AUTOSAR XML (schema 4-3-0)
standard types defined: UINT8, UINT16, UINT32, UINT64, SINT8, SINT16, SINT32, FLOAT32, FLOAT64
package /Pkg_ErrorMgrAgg_1_0_QM/ComponentTypes
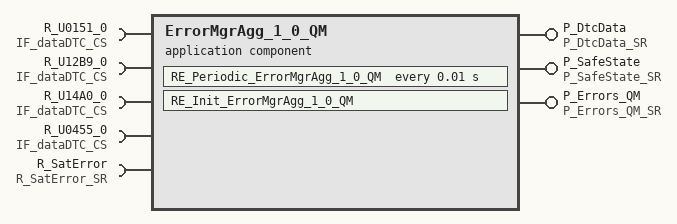
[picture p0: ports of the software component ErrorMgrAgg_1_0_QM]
  application sw component type ErrorMgrAgg_1_0_QM
    provide port P_DtcData: provided-interface=P_DtcData_SR
      provided-com-specs:
        data-element=Data_DtcStatus_QM, init-value=constant-reference=init_Data_DtcStatus_QM
        data-element=Data_DtcAddData_QM, init-value=constant-reference=init_Data_DtcAddData_QM
    provide port P_SafeState: nonqueued-sender-com-spec{data-element=SafeStateOp, init-value=constant-reference=init_SafeStateOp}, provided-interface=P_SafeState_SR
    provide port P_Errors_QM: nonqueued-sender-com-spec=data-element=Errors_QM, provided-interface=P_Errors_QM_SR
    5 x require port:
      R_U0151_0: client-com-spec=dTCinfo_v, required-interface=IF_dataDTC_CS
      R_U12B9_0: client-com-spec=dTCinfo_v, required-interface=IF_dataDTC_CS
      R_U14A0_0: client-com-spec=dTCinfo_v, required-interface=IF_dataDTC_CS
      R_U0455_0: client-com-spec=dTCinfo_v, required-interface=IF_dataDTC_CS
      R_SatError: required-interface=R_SatError_SR
        required-com-specs:
          data-element=Data_ErrorMgr_ErrorCommPack_1_0_QM, init-value=constant-reference=init_Data_ErrorMgr_ErrorCommPack_1_0_QM
          data-element=Data_ErrorMgr_ErrorCommPack_2_0_QM, init-value=constant-reference=init_Data_ErrorMgr_ErrorCommPack_2_0_QM
          data-element=Data_ErrorMgr_ErrorCommPack_2_1_QM, init-value=constant-reference=init_Data_ErrorMgr_ErrorCommPack_2_1_QM
          data-element=Data_ErrorMgr_ErrorCommPack_QNX_QM, init-value=constant-reference=init_Data_ErrorMgr_ErrorCommPack_QNX_QM
    behavior ErrorMgrAgg_1_0_QM_InternalBehavior: handle-termination-and-restart=NO-SUPPORT
      timing event TMT_RE_Periodic_ErrorMgrAgg_1_0_QM: start-on-event=RE_Periodic_ErrorMgrAgg_1_0_QM, period=0.01
      init event InitEvent: start-on-event=RE_Init_ErrorMgrAgg_1_0_QM
      port-api-options:
        enable-take-address=false, indirect-api=false, port=P_DtcData
        enable-take-address=false, indirect-api=false, port=P_Errors_QM
        enable-take-address=false, indirect-api=false, port=P_SafeState
        enable-take-address=false, indirect-api=false, port=R_SatError
        enable-take-address=false, indirect-api=false, port=R_U0151_0
        enable-take-address=false, indirect-api=false, port=R_U0455_0
        enable-take-address=false, indirect-api=false, port=R_U12B9_0
        enable-take-address=false, indirect-api=false, port=R_U14A0_0
      runnable RE_Periodic_ErrorMgrAgg_1_0_QM  # Periodic Runnable of Satellite
        data-receive-point-by-arguments:
          4 x access:
            REC_R_SatError_Data_ErrorMgr_ErrorCommPack_1_0_QM: accessed-variable=R_SatError.Data_ErrorMgr_ErrorCommPack_1_0_QM
            REC_R_SatError_Data_ErrorMgr_ErrorCommPack_2_0_QM: accessed-variable=R_SatError.Data_ErrorMgr_ErrorCommPack_2_0_QM
            REC_R_SatError_Data_ErrorMgr_ErrorCommPack_2_1_QM: accessed-variable=R_SatError.Data_ErrorMgr_ErrorCommPack_2_1_QM
            REC_R_SatError_Data_ErrorMgr_ErrorCommPack_QNX_QM: accessed-variable=R_SatError.Data_ErrorMgr_ErrorCommPack_QNX_QM
        data-send-points:
          4 x access:
            SEND_P_DtcData_Data_DtcStatus_QM: accessed-variable=P_DtcData.Data_DtcStatus_QM
            SEND_P_DtcData_Data_DtcAddData_QM: accessed-variable=P_DtcData.Data_DtcAddData_QM
            SEND_P_SafeState_SafeStateOp: accessed-variable=P_SafeState.SafeStateOp
            SEND_P_Errors_QM_Errors_QM: accessed-variable=P_Errors_QM.Errors_QM
        4 x sync call, all with timeout=0:
          SC_R_U0151_0_dTCinfo_v: operation=R_U0151_0.dTCinfo_v
          SC_R_U12B9_0_dTCinfo_v: operation=R_U12B9_0.dTCinfo_v
          SC_R_U14A0_0_dTCinfo_v: operation=R_U14A0_0.dTCinfo_v
          SC_R_U0455_0_dTCinfo_v: operation=R_U0455_0.dTCinfo_v
      runnable RE_Init_ErrorMgrAgg_1_0_QM  # Init Runnable
  swc implementation ErrorMgrAgg_1_0_QM_Implementation: programming-language=C, vendor-id=0, behavior=ErrorMgrAgg_1_0_QM_InternalBehavior
    code-descriptors:
      code Default: artifact-descriptors=autosar-engineering-object={short-label=Default, category=SWSRC}
package /Pkg_ErrorMgrAgg_1_0_QM/Constant
  8 x constant specification:
    init_Data_DtcStatus_QM: value-spec=fields=[0, 0, 0, 0]
    init_Data_DtcAddData_QM: value-spec=fields=[[0, 0, 0, 0], [0, 0, 0, 0], [0, 0, 0, 0], [0, 0, 0, 0]]
    init_SafeStateOp: value-spec=fields=16 x 0
    init_Errors_QM: value-spec=[0]
    init_Data_ErrorMgr_ErrorCommPack_1_0_QM: value-spec=fields=[0, 0, 12 x 0, 12 x fields=[0, 0, 0, 0]]
    init_Data_ErrorMgr_ErrorCommPack_2_0_QM: value-spec=fields=[0, 0, [0], [0, 0, 0], [fields=[0, 0, 0, 0]]]
    init_Data_ErrorMgr_ErrorCommPack_2_1_QM: value-spec=fields=[0, 0, [0], [0, 0, 0], [fields=[0, 0, 0, 0]]]
    init_Data_ErrorMgr_ErrorCommPack_QNX_QM: value-spec=fields=[0, 0, [0], [0, 0, 0], [fields=[0, 0, 0, 0]]]
package /Pkg_ErrorMgrAgg_1_0_QM/ImplementationDataTypes
  34 x impl type, all with type-emitter=RTE:
    BOOL: implementation-data-type=boolean
    ErrorMgr_ErrorField: implementation-data-type=uint8
    Error1_0QM_arr: category=ARRAY
      element Elem_ErrorMgr_ErrorField: array-size=12, array-size-semantics=FIXED-SIZE, implementation-data-type=ErrorMgr_ErrorField
    Data1_0QM_arr: category=ARRAY
      element Elem_ErrorMgr_stAddData: array-size=12, array-size-semantics=FIXED-SIZE, implementation-data-type=ErrorMgr_stAddData
    Error1_0B_arr: category=ARRAY
      element Elem_ErrorMgr_ErrorField: array-size=400, array-size-semantics=FIXED-SIZE, implementation-data-type=ErrorMgr_ErrorField
    Data1_0B_arr: category=ARRAY
      element Elem_ErrorMgr_stAddData: array-size=400, array-size-semantics=FIXED-SIZE, implementation-data-type=ErrorMgr_stAddData
    Error2_0QM_arr: category=ARRAY
      element Elem_ErrorMgr_ErrorField: array-size=1, array-size-semantics=FIXED-SIZE, implementation-data-type=ErrorMgr_ErrorField
    Padding2_0QM_arr: category=ARRAY
      element Elem_ErrorMgr_ErrorField: array-size=3, array-size-semantics=FIXED-SIZE, implementation-data-type=ErrorMgr_ErrorField
    Data2_0QM_arr: category=ARRAY
      element Elem_ErrorMgr_stAddData: array-size=1, array-size-semantics=FIXED-SIZE, implementation-data-type=ErrorMgr_stAddData
    Error2_0B_arr: category=ARRAY
      element Elem_ErrorMgr_ErrorField: array-size=144, array-size-semantics=FIXED-SIZE, implementation-data-type=ErrorMgr_ErrorField
    Data2_0B_arr: category=ARRAY
      element Elem_ErrorMgr_stAddData: array-size=144, array-size-semantics=FIXED-SIZE, implementation-data-type=ErrorMgr_stAddData
    Error2_1QM_arr: category=ARRAY
      element Elem_ErrorMgr_ErrorField: array-size=1, array-size-semantics=FIXED-SIZE, implementation-data-type=ErrorMgr_ErrorField
    Padding2_1QM_arr: category=ARRAY
      element Elem_ErrorMgr_ErrorField: array-size=3, array-size-semantics=FIXED-SIZE, implementation-data-type=ErrorMgr_ErrorField
    Data2_1QM_arr: category=ARRAY
      element Elem_ErrorMgr_stAddData: array-size=1, array-size-semantics=FIXED-SIZE, implementation-data-type=ErrorMgr_stAddData
    Error2_1B_arr: category=ARRAY
      element Elem_ErrorMgr_ErrorField: array-size=548, array-size-semantics=FIXED-SIZE, implementation-data-type=ErrorMgr_ErrorField
    Data2_1B_arr: category=ARRAY
      element Elem_ErrorMgr_stAddData: array-size=548, array-size-semantics=FIXED-SIZE, implementation-data-type=ErrorMgr_stAddData
    ErrorQNXQM_arr: category=ARRAY
      element Elem_ErrorMgr_ErrorField: array-size=1, array-size-semantics=FIXED-SIZE, implementation-data-type=ErrorMgr_ErrorField
    PaddingQNXQM_arr: category=ARRAY
      element Elem_ErrorMgr_ErrorField: array-size=3, array-size-semantics=FIXED-SIZE, implementation-data-type=ErrorMgr_ErrorField
    DataQNXQM_arr: category=ARRAY
      element Elem_ErrorMgr_stAddData: array-size=1, array-size-semantics=FIXED-SIZE, implementation-data-type=ErrorMgr_stAddData
    ErrorQNXB_arr: category=ARRAY
      element Elem_ErrorMgr_ErrorField: array-size=8, array-size-semantics=FIXED-SIZE, implementation-data-type=ErrorMgr_ErrorField
    DataQNXB_arr: category=ARRAY
      element Elem_ErrorMgr_stAddData: array-size=8, array-size-semantics=FIXED-SIZE, implementation-data-type=ErrorMgr_stAddData
    AdditionalData_arr: category=ARRAY
      element Elem_uint8: array-size=4, array-size-semantics=FIXED-SIZE, implementation-data-type=uint8
    SafeStateActive_arr: category=ARRAY
      element Elem_uint8: array-size=16, array-size-semantics=FIXED-SIZE, implementation-data-type=uint8
    ErrorListArr_QM: category=ARRAY
      element Elem_uint32: array-size=1, array-size-semantics=FIXED-SIZE, implementation-data-type=uint32
    ErrorMgr_enSafeStates: compu {0=ErrorMgr_SafeState_safestate1, 1=ErrorMgr_SafeState_safestate16, 2=ErrorMgr_SafeState_safestate23, 3=ErrorMgr_SafeState_safestate24, 4=ErrorMgr_SafeState_safestate17, 5=ErrorMgr_SafeState_safestate13, 6=ErrorMgr_SafeState_safestate12, 7=ErrorMgr_SafeState_safestate9, 8=ErrorMgr_SafeState_safestate10, 9=ErrorMgr_SafeState_safestate7, 10=ErrorMgr_SafeState_safestate4, 11=ErrorMgr_SafeState_safestate2, 12=ErrorMgr_SafeState_safestate5, 13=ErrorMgr_SafeState_safestate11, 14=ErrorMgr_SafeState_safestate21, 15=ErrorMgr_SafeState_Max}, implementation-data-type=uint32
    ErrorMgr_enErrorStatus: compu {0=ErrorMgr_Invalid, 1=ErrorMgr_ErrorInactive, 2=ErrorMgr_ErrorActive}, implementation-data-type=uint32
    ErrorMgr_ErrorCommPack_1_0_QM: category=STRUCTURE
      4 x element, all with category=TYPE_REFERENCE:
        RunningCounter: implementation-data-type=uint32
        Checksum: implementation-data-type=uint32
        Error: implementation-data-type=Error1_0QM_arr
        Data: implementation-data-type=Data1_0QM_arr
    ErrorMgr_ErrorCommPack_2_0_QM: category=STRUCTURE
      5 x element, all with category=TYPE_REFERENCE:
        RunningCounter: implementation-data-type=uint32
        Checksum: implementation-data-type=uint32
        Error: implementation-data-type=Error2_0QM_arr
        Padding: implementation-data-type=Padding2_0QM_arr
        Data: implementation-data-type=Data2_0QM_arr
    ErrorMgr_ErrorCommPack_2_1_QM: category=STRUCTURE
      5 x element, all with category=TYPE_REFERENCE:
        RunningCounter: implementation-data-type=uint32
        Checksum: implementation-data-type=uint32
        Error: implementation-data-type=Error2_1QM_arr
        Padding: implementation-data-type=Padding2_1QM_arr
        Data: implementation-data-type=Data2_1QM_arr
    ErrorMgr_ErrorCommPack_QNX_QM: category=STRUCTURE
      5 x element, all with category=TYPE_REFERENCE:
        RunningCounter: implementation-data-type=uint32
        Checksum: implementation-data-type=uint32
        Error: implementation-data-type=ErrorQNXQM_arr
        Padding: implementation-data-type=PaddingQNXQM_arr
        Data: implementation-data-type=DataQNXQM_arr
    SafeStateOpDef: category=STRUCTURE
      element SafeStateActive: implementation-data-type=SafeStateActive_arr
    ErrorMgr_stAddData: category=STRUCTURE
      element AdditionalData: implementation-data-type=AdditionalData_arr
    DtcStatus_QM: category=STRUCTURE
      4 x element, all with category=TYPE_REFERENCE, implementation-data-type=uint8:
        u0151_0_0
        u12b9_0_0
        u14a0_0_0
        u0455_0_0
    DtcAddData_QM: category=STRUCTURE
      4 x element, all with category=TYPE_REFERENCE, implementation-data-type=AdditionalData_arr:
        u0151_0_0
        u12b9_0_0
        u14a0_0_0
        u0455_0_0
package /Pkg_ErrorMgrAgg_1_0_QM/PortInterfaces
  4 x sender receiver interface:
    R_SatError_SR  # Comments
      4 x data:
        Data_ErrorMgr_ErrorCommPack_1_0_QM: type=ErrorMgr_ErrorCommPack_1_0_QM
        Data_ErrorMgr_ErrorCommPack_2_0_QM: type=ErrorMgr_ErrorCommPack_2_0_QM
        Data_ErrorMgr_ErrorCommPack_2_1_QM: type=ErrorMgr_ErrorCommPack_2_1_QM
        Data_ErrorMgr_ErrorCommPack_QNX_QM: type=ErrorMgr_ErrorCommPack_QNX_QM
    P_DtcData_SR  # Port for reading DTC Data
      data Data_DtcStatus_QM: type=DtcStatus_QM
      data Data_DtcAddData_QM: type=DtcAddData_QM
    P_SafeState_SR  # Safe State Outputs
      data SafeStateOp: type=SafeStateOpDef
    P_Errors_QM_SR  # Status of Errors
      data Errors_QM: type=ErrorListArr_QM
